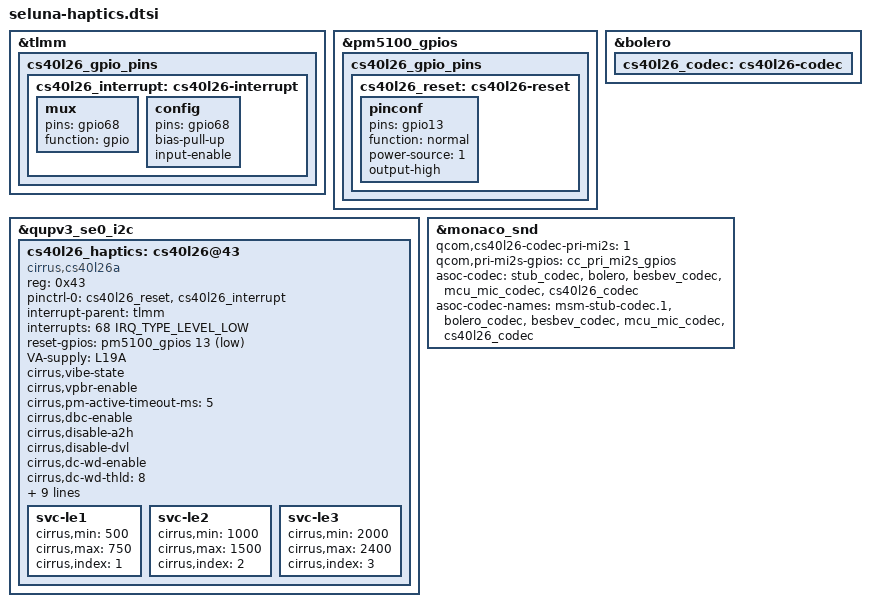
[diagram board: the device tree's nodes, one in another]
// SPDX-License-Identifier: GPL-2.0

#include <dt-bindings/interrupt-controller/irq.h>

&tlmm {
	cs40l26_gpio_pins {
		cs40l26_interrupt: cs40l26-interrupt {
			mux {
				pins = "gpio68";
				function = "gpio";
			};

			config {
				pins = "gpio68";
				bias-pull-up;
				input-enable;
			};
		};
	};
};

&pm5100_gpios {
	cs40l26_gpio_pins {
		cs40l26_reset: cs40l26-reset {
			pinconf {
				pins = "gpio13";
				function = "normal";
				power-source = <1>; /* VREG_L19A */
				output-high;
			};
		};
	};
};

&qupv3_se0_i2c {
	#address-cells = <1>;
	#size-cells = <0>;

	status = "ok";

	cs40l26_haptics: cs40l26@43 {
		compatible = "cirrus,cs40l26a";
		reg = <0x43>;
		pinctrl-names = "default";
		pinctrl-0 = <&cs40l26_reset>, <&cs40l26_interrupt>;
		interrupt-parent = <&tlmm>;
		interrupts = <68 IRQ_TYPE_LEVEL_LOW>;
		reset-gpios = <&pm5100_gpios 13 GPIO_ACTIVE_LOW>;
		VA-supply = <&L19A>;

		cirrus,vibe-state;

		cirrus,vpbr-enable;

		cirrus,pm-active-timeout-ms=<5>;

		cirrus,dbc-enable;

		cirrus,disable-a2h;
		cirrus,disable-dvl;

		cirrus,dc-wd-enable;
		cirrus,dc-wd-thld = <8>; // 8 * 2.5 % = 20%
		cirrus,dc-wd-dur = <3>;  // [0 1 1] is the reserved enum for 195 ms
		cirrus,dc-wd-mute;       // Mute mode - remove for normal mode

		cirrus,pwle-zero-cross-en;

		cirrus,bst-dcm-en;
		cirrus,vpbr-thld-uv = <3000000>;        // 3V
		cirrus,bst-ipk-microamp = <1350000>;    // 1.35A
		cirrus,bst-ctl-microvolt = <10000000>;  // 10V
		cirrus,f0-default = <0x258000>;         // 150 Hz
		cirrus,redc-default = <0x76000>;        // 14.75 Ohm

		svc-le1 {
			cirrus,min = <500>; //59.6 uH
			cirrus,max = <750>; //89.4 uH
			cirrus,index = <1>;
		};
		svc-le2 {
			cirrus,min = <1000>; //119.2 uH
			cirrus,max = <1500>; //178.8 uH
			cirrus,index = <2>;
		};
		svc-le3 {
			cirrus,min = <2000>; //238.4 uH
			cirrus,max = <2400>; //286.1 uH
			cirrus,index = <3>;
		};
	};
};

&bolero {
	cs40l26_codec: cs40l26-codec {
		status = "ok";
	};
};

&monaco_snd {
	qcom,cs40l26-codec-pri-mi2s = <1>;
	qcom,pri-mi2s-gpios = <&cc_pri_mi2s_gpios>;

	asoc-codec  = <&stub_codec>, <&bolero>,
			<&besbev_codec>, <&mcu_mic_codec>, <&cs40l26_codec>;
	asoc-codec-names = "msm-stub-codec.1", "bolero_codec",
				"besbev_codec", "mcu_mic_codec", "cs40l26_codec";
};
